AUTOSAR XML (schema 00044)
package /ComponentTypes
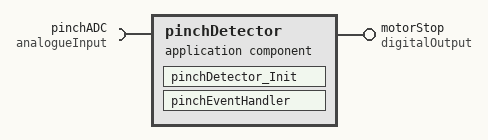
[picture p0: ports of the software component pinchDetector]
  application sw component type pinchDetector
    require port pinchADC: nonqueued-receiver-com-spec=data-element=ADCinput, required-interface=analogueInput
    provide port motorStop: nonqueued-sender-com-spec=outputStatus, provided-interface=digitalOutput
    behavior pinchDetector_InternalBehavior
      init event pinchDetector_InitEvent: start-on-event=pinchDetector_Init
      data received event DRT_pinchEventHandler_pinchADC_ADCinput: start-on-event=pinchEventHandler, data=pinchADC.ADCinput
      runnable pinchDetector_Init
        data-send-points:
          access SEND_motorStop_outputStatus: accessed-variable=motorStop.outputStatus
      runnable pinchEventHandler
        data-receive-point-by-values:
          access REC_pinchADC_ADCinput: accessed-variable=pinchADC.ADCinput
        data-send-points:
          access SEND_motorStop_outputStatus: accessed-variable=motorStop.outputStatus
  swc implementation pinchDetector_Implementation: behavior=pinchDetector_InternalBehavior
